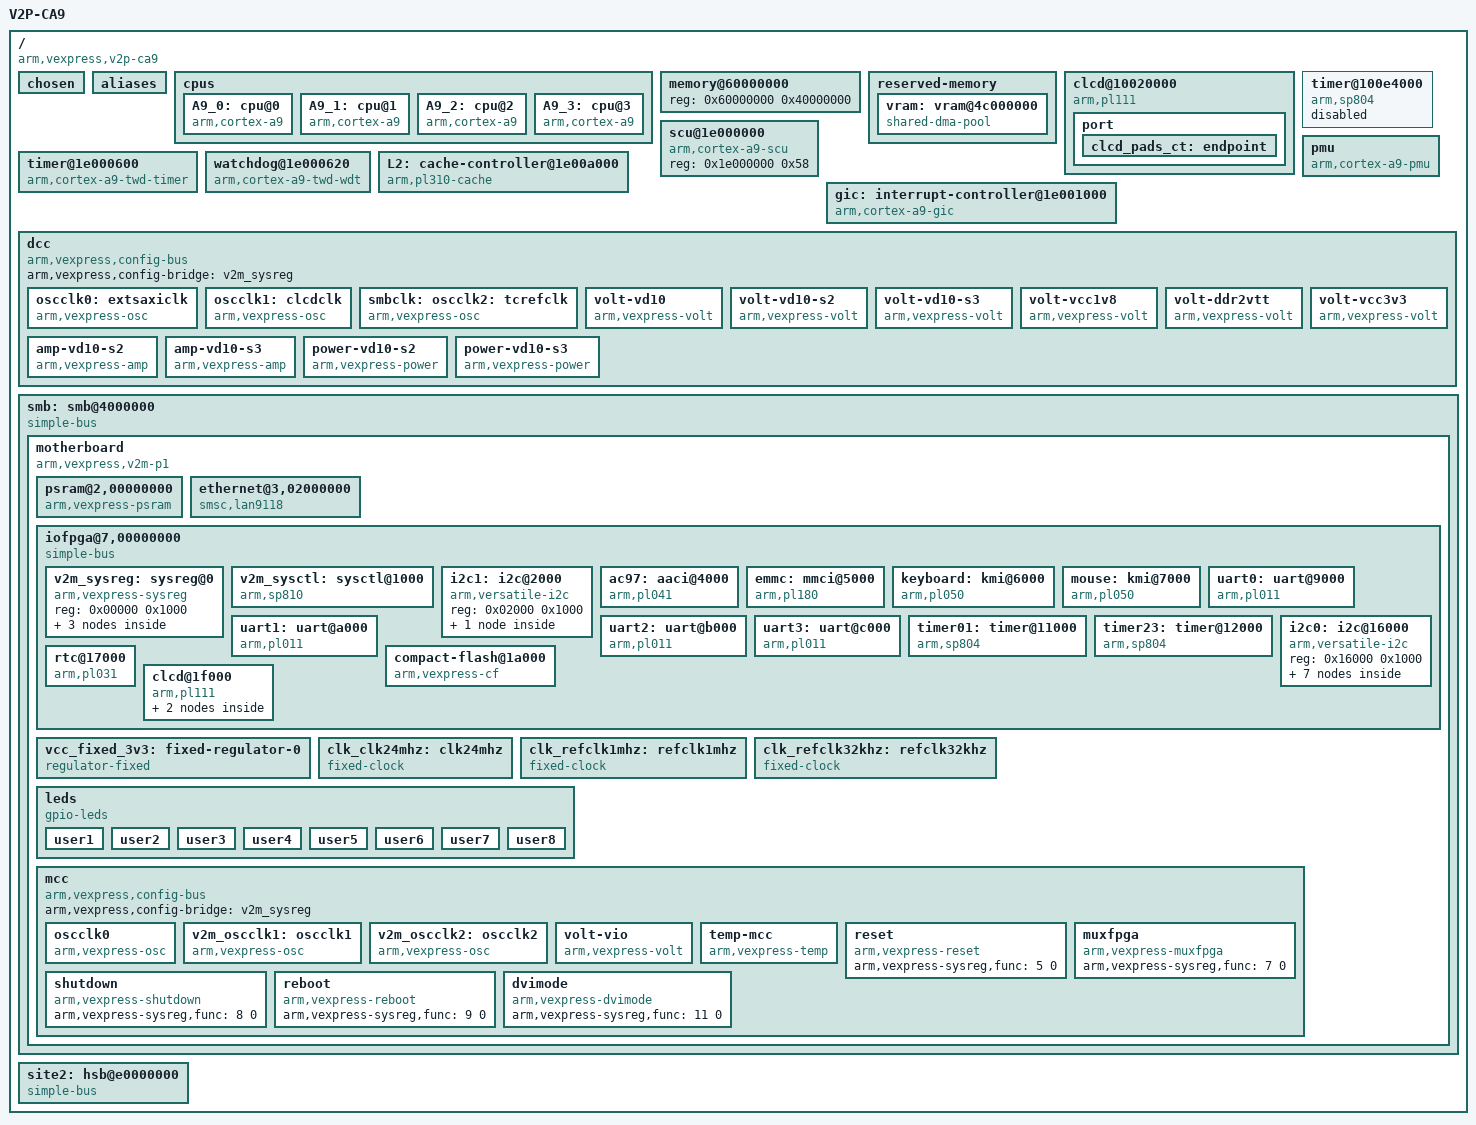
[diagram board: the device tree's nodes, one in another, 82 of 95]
// SPDX-License-Identifier: GPL-2.0
/*
 * ARM Ltd. Versatile Express
 *
 * CoreTile Express A9x4
 * Cortex-A9 MPCore (V2P-CA9)
 *
 * HBI-0191B
 */

/dts-v1/;

/ {
	model = "V2P-CA9";
	arm,hbi = <0x191>;
	arm,vexpress,site = <0xf>;
	compatible = "arm,vexpress,v2p-ca9", "arm,vexpress";
	interrupt-parent = <&gic>;
	#address-cells = <1>;
	#size-cells = <1>;

	chosen { };

	aliases {
		serial0 = &uart0;
		serial1 = &uart1;
		serial2 = &uart2;
		serial3 = &uart3;
		i2c0 = &i2c0;
		i2c1 = &i2c1;
	};

	cpus {
		#address-cells = <1>;
		#size-cells = <0>;

		A9_0: cpu@0 {
			device_type = "cpu";
			compatible = "arm,cortex-a9";
			reg = <0>;
			next-level-cache = <&L2>;
		};

		A9_1: cpu@1 {
			device_type = "cpu";
			compatible = "arm,cortex-a9";
			reg = <1>;
			next-level-cache = <&L2>;
		};

		A9_2: cpu@2 {
			device_type = "cpu";
			compatible = "arm,cortex-a9";
			reg = <2>;
			next-level-cache = <&L2>;
		};

		A9_3: cpu@3 {
			device_type = "cpu";
			compatible = "arm,cortex-a9";
			reg = <3>;
			next-level-cache = <&L2>;
		};
	};

	memory@60000000 {
		device_type = "memory";
		reg = <0x60000000 0x40000000>;
	};

	reserved-memory {
		#address-cells = <1>;
		#size-cells = <1>;
		ranges;

		/* Chipselect 3 is physically at 0x4c000000 */
		vram: vram@4c000000 {
			/* 8 MB of designated video RAM */
			compatible = "shared-dma-pool";
			reg = <0x4c000000 0x00800000>;
			no-map;
		};
	};

	clcd@10020000 {
		compatible = "arm,pl111", "arm,primecell";
		reg = <0x10020000 0x1000>;
		interrupt-names = "combined";
		interrupts = <0 44 4>;
		clocks = <&oscclk1>, <&oscclk2>;
		clock-names = "clcdclk", "apb_pclk";
		/* 1024x768 16bpp @65MHz */
		max-memory-bandwidth = <95000000>;

		port {
			clcd_pads_ct: endpoint {
				remote-endpoint = <&dvi_bridge_in_ct>;
				arm,pl11x,tft-r0g0b0-pads = <0 8 16>;
			};
		};
	};

	timer@100e4000 {
		compatible = "arm,sp804", "arm,primecell";
		reg = <0x100e4000 0x1000>;
		interrupts = <0 48 4>,
			     <0 49 4>;
		clocks = <&oscclk2>, <&oscclk2>;
		clock-names = "timclk", "apb_pclk";
		status = "disabled";
	};

	scu@1e000000 {
		compatible = "arm,cortex-a9-scu";
		reg = <0x1e000000 0x58>;
	};

	timer@1e000600 {
		compatible = "arm,cortex-a9-twd-timer";
		reg = <0x1e000600 0x20>;
		interrupts = <1 13 0xf04>;
	};

	watchdog@1e000620 {
		compatible = "arm,cortex-a9-twd-wdt";
		reg = <0x1e000620 0x20>;
		interrupts = <1 14 0xf04>;
	};

	gic: interrupt-controller@1e001000 {
		compatible = "arm,cortex-a9-gic";
		#interrupt-cells = <3>;
		#address-cells = <0>;
		interrupt-controller;
		reg = <0x1e001000 0x1000>,
		      <0x1e000100 0x100>;
	};

	L2: cache-controller@1e00a000 {
		compatible = "arm,pl310-cache";
		reg = <0x1e00a000 0x1000>;
		interrupts = <0 43 4>;
		cache-unified;
		cache-level = <2>;
		arm,data-latency = <1 1 1>;
		arm,tag-latency = <1 1 1>;
	};

	pmu {
		compatible = "arm,cortex-a9-pmu";
		interrupts = <0 60 4>,
			     <0 61 4>,
			     <0 62 4>,
			     <0 63 4>;
		interrupt-affinity = <&A9_0>, <&A9_1>, <&A9_2>, <&A9_3>;
	};

	dcc {
		compatible = "arm,vexpress,config-bus";
		arm,vexpress,config-bridge = <&v2m_sysreg>;

		oscclk0: extsaxiclk {
			/* ACLK clock to the AXI master port on the test chip */
			compatible = "arm,vexpress-osc";
			arm,vexpress-sysreg,func = <1 0>;
			freq-range = <30000000 50000000>;
			#clock-cells = <0>;
			clock-output-names = "extsaxiclk";
		};

		oscclk1: clcdclk {
			/* Reference clock for the CLCD */
			compatible = "arm,vexpress-osc";
			arm,vexpress-sysreg,func = <1 1>;
			freq-range = <10000000 80000000>;
			#clock-cells = <0>;
			clock-output-names = "clcdclk";
		};

		smbclk: oscclk2: tcrefclk {
			/* Reference clock for the test chip internal PLLs */
			compatible = "arm,vexpress-osc";
			arm,vexpress-sysreg,func = <1 2>;
			freq-range = <33000000 100000000>;
			#clock-cells = <0>;
			clock-output-names = "tcrefclk";
		};

		volt-vd10 {
			/* Test Chip internal logic voltage */
			compatible = "arm,vexpress-volt";
			arm,vexpress-sysreg,func = <2 0>;
			regulator-name = "VD10";
			regulator-always-on;
			label = "VD10";
		};

		volt-vd10-s2 {
			/* PL310, L2 cache, RAM cell supply (not PL310 logic) */
			compatible = "arm,vexpress-volt";
			arm,vexpress-sysreg,func = <2 1>;
			regulator-name = "VD10_S2";
			regulator-always-on;
			label = "VD10_S2";
		};

		volt-vd10-s3 {
			/* Cortex-A9 system supply, Cores, MPEs, SCU and PL310 logic */
			compatible = "arm,vexpress-volt";
			arm,vexpress-sysreg,func = <2 2>;
			regulator-name = "VD10_S3";
			regulator-always-on;
			label = "VD10_S3";
		};

		volt-vcc1v8 {
			/* DDR2 SDRAM and Test Chip DDR2 I/O supply */
			compatible = "arm,vexpress-volt";
			arm,vexpress-sysreg,func = <2 3>;
			regulator-name = "VCC1V8";
			regulator-always-on;
			label = "VCC1V8";
		};

		volt-ddr2vtt {
			/* DDR2 SDRAM VTT termination voltage */
			compatible = "arm,vexpress-volt";
			arm,vexpress-sysreg,func = <2 4>;
			regulator-name = "DDR2VTT";
			regulator-always-on;
			label = "DDR2VTT";
		};

		volt-vcc3v3 {
			/* Local board supply for miscellaneous logic external to the Test Chip */
			arm,vexpress-sysreg,func = <2 5>;
			compatible = "arm,vexpress-volt";
			regulator-name = "VCC3V3";
			regulator-always-on;
			label = "VCC3V3";
		};

		amp-vd10-s2 {
			/* PL310, L2 cache, RAM cell supply (not PL310 logic) */
			compatible = "arm,vexpress-amp";
			arm,vexpress-sysreg,func = <3 0>;
			label = "VD10_S2";
		};

		amp-vd10-s3 {
			/* Cortex-A9 system supply, Cores, MPEs, SCU and PL310 logic */
			compatible = "arm,vexpress-amp";
			arm,vexpress-sysreg,func = <3 1>;
			label = "VD10_S3";
		};

		power-vd10-s2 {
			/* PL310, L2 cache, RAM cell supply (not PL310 logic) */
			compatible = "arm,vexpress-power";
			arm,vexpress-sysreg,func = <12 0>;
			label = "PVD10_S2";
		};

		power-vd10-s3 {
			/* Cortex-A9 system supply, Cores, MPEs, SCU and PL310 logic */
			compatible = "arm,vexpress-power";
			arm,vexpress-sysreg,func = <12 1>;
			label = "PVD10_S3";
		};
	};

	smb: smb@4000000 {
		compatible = "simple-bus";

		#address-cells = <2>;
		#size-cells = <1>;
		ranges = <0 0 0x40000000 0x04000000>,
			 <1 0 0x44000000 0x04000000>,
			 <2 0 0x48000000 0x04000000>,
			 <3 0 0x4c000000 0x04000000>,
			 <7 0 0x10000000 0x00020000>;

		#interrupt-cells = <1>;
		interrupt-map-mask = <0 0 63>;
		interrupt-map = <0 0  0 &gic 0  0 4>,
				<0 0  1 &gic 0  1 4>,
				<0 0  2 &gic 0  2 4>,
				<0 0  3 &gic 0  3 4>,
				<0 0  4 &gic 0  4 4>,
				<0 0  5 &gic 0  5 4>,
				<0 0  6 &gic 0  6 4>,
				<0 0  7 &gic 0  7 4>,
				<0 0  8 &gic 0  8 4>,
				<0 0  9 &gic 0  9 4>,
				<0 0 10 &gic 0 10 4>,
				<0 0 11 &gic 0 11 4>,
				<0 0 12 &gic 0 12 4>,
				<0 0 13 &gic 0 13 4>,
				<0 0 14 &gic 0 14 4>,
				<0 0 15 &gic 0 15 4>,
				<0 0 16 &gic 0 16 4>,
				<0 0 17 &gic 0 17 4>,
				<0 0 18 &gic 0 18 4>,
				<0 0 19 &gic 0 19 4>,
				<0 0 20 &gic 0 20 4>,
				<0 0 21 &gic 0 21 4>,
				<0 0 22 &gic 0 22 4>,
				<0 0 23 &gic 0 23 4>,
				<0 0 24 &gic 0 24 4>,
				<0 0 25 &gic 0 25 4>,
				<0 0 26 &gic 0 26 4>,
				<0 0 27 &gic 0 27 4>,
				<0 0 28 &gic 0 28 4>,
				<0 0 29 &gic 0 29 4>,
				<0 0 30 &gic 0 30 4>,
				<0 0 31 &gic 0 31 4>,
				<0 0 32 &gic 0 32 4>,
				<0 0 33 &gic 0 33 4>,
				<0 0 34 &gic 0 34 4>,
				<0 0 35 &gic 0 35 4>,
				<0 0 36 &gic 0 36 4>,
				<0 0 37 &gic 0 37 4>,
				<0 0 38 &gic 0 38 4>,
				<0 0 39 &gic 0 39 4>,
				<0 0 40 &gic 0 40 4>,
				<0 0 41 &gic 0 41 4>,
				<0 0 42 &gic 0 42 4>;

		motherboard {
			model = "V2M-P1";
			arm,hbi = <0x190>;
			arm,vexpress,site = <0>;
			compatible = "arm,vexpress,v2m-p1", "simple-bus";
			#address-cells = <2>; /* SMB chipselect number and offset */
			#size-cells = <1>;
			#interrupt-cells = <1>;
			ranges;

			psram@2,00000000 {
				compatible = "arm,vexpress-psram", "mtd-ram";
				reg = <2 0x00000000 0x02000000>;
				bank-width = <4>;
			};

			ethernet@3,02000000 {
				compatible = "smsc,lan9118", "smsc,lan9115";
				reg = <3 0x02000000 0x10000>;
				interrupts = <15>;
				phy-mode = "mii";
				reg-io-width = <4>;
				smsc,irq-active-high;
				smsc,irq-push-pull;
				vdd33a-supply = <&vcc_fixed_3v3>;
				vddvario-supply = <&vcc_fixed_3v3>;
			};

			iofpga@7,00000000 {
				compatible = "simple-bus";
				#address-cells = <1>;
				#size-cells = <1>;
				ranges = <0 7 0 0x20000>;

				v2m_sysreg: sysreg@0 {
					compatible = "arm,vexpress-sysreg";
					reg = <0x00000 0x1000>;
					#address-cells = <1>;
					#size-cells = <1>;
					ranges = <0 0 0x1000>;

					v2m_led_gpios: gpio@8 {
						compatible = "arm,vexpress-sysreg,sys_led";
						reg = <0x008 4>;
						gpio-controller;
						#gpio-cells = <2>;
					};

					v2m_mmc_gpios: gpio@48 {
						compatible = "arm,vexpress-sysreg,sys_mci";
						reg = <0x048 4>;
						gpio-controller;
						#gpio-cells = <2>;
					};

					v2m_flash_gpios: gpio@4c {
						compatible = "arm,vexpress-sysreg,sys_flash";
						reg = <0x04c 4>;
						gpio-controller;
						#gpio-cells = <2>;
					};
				};

				v2m_sysctl: sysctl@1000 {
					compatible = "arm,sp810", "arm,primecell";
					reg = <0x01000 0x1000>;
					clocks = <&clk_refclk32khz>, <&clk_refclk1mhz>, <&smbclk>;
					clock-names = "refclk", "timclk", "apb_pclk";
					#clock-cells = <1>;
					clock-output-names = "timerclken0", "timerclken1", "timerclken2", "timerclken3";
					assigned-clocks = <&v2m_sysctl 0>, <&v2m_sysctl 1>, <&v2m_sysctl 3>, <&v2m_sysctl 3>;
					assigned-clock-parents = <&clk_refclk1mhz>, <&clk_refclk1mhz>, <&clk_refclk1mhz>, <&clk_refclk1mhz>;
				};

				/* PCI-E I2C bus */
				i2c1: i2c@2000 {
					compatible = "arm,versatile-i2c";
					reg = <0x02000 0x1000>;

					#address-cells = <1>;
					#size-cells = <0>;

					pcie-switch@60 {
						compatible = "idt,89hpes32h8";
						reg = <0x60>;
					};
				};

				ac97: aaci@4000 {
					compatible = "arm,pl041", "arm,primecell";
					reg = <0x04000 0x1000>;
					interrupts = <11>;
					clocks = <&smbclk>;
					clock-names = "apb_pclk";
				};

				emmc: mmci@5000 {
					compatible = "arm,pl180", "arm,primecell";
					reg = <0x05000 0x1000>;
					interrupts = <9>, <10>;
					cd-gpios = <&v2m_mmc_gpios 0 0>;
					wp-gpios = <&v2m_mmc_gpios 1 0>;
					max-frequency = <12000000>;
					vmmc-supply = <&vcc_fixed_3v3>;
					clocks = <&clk_clk24mhz>, <&smbclk>;
					clock-names = "mclk", "apb_pclk";
				};

				keyboard: kmi@6000 {
					compatible = "arm,pl050", "arm,primecell";
					reg = <0x06000 0x1000>;
					interrupts = <12>;
					clocks = <&clk_clk24mhz>, <&smbclk>;
					clock-names = "KMIREFCLK", "apb_pclk";
				};

				mouse: kmi@7000 {
					compatible = "arm,pl050", "arm,primecell";
					reg = <0x07000 0x1000>;
					interrupts = <13>;
					clocks = <&clk_clk24mhz>, <&smbclk>;
					clock-names = "KMIREFCLK", "apb_pclk";
				};

				uart0: uart@9000 {
					compatible = "arm,pl011", "arm,primecell";
					reg = <0x09000 0x1000>;
					interrupts = <5>;
					clocks = <&v2m_oscclk2>, <&smbclk>;
					clock-names = "uartclk", "apb_pclk";
				};

				uart1: uart@a000 {
					compatible = "arm,pl011", "arm,primecell";
					reg = <0x0a000 0x1000>;
					interrupts = <6>;
					clocks = <&v2m_oscclk2>, <&smbclk>;
					clock-names = "uartclk", "apb_pclk";
				};

				uart2: uart@b000 {
					compatible = "arm,pl011", "arm,primecell";
					reg = <0x0b000 0x1000>;
					interrupts = <7>;
					clocks = <&v2m_oscclk2>, <&smbclk>;
					clock-names = "uartclk", "apb_pclk";
				};

				uart3: uart@c000 {
					compatible = "arm,pl011", "arm,primecell";
					reg = <0x0c000 0x1000>;
					interrupts = <8>;
					clocks = <&v2m_oscclk2>, <&smbclk>;
					clock-names = "uartclk", "apb_pclk";
				};

				timer01: timer@11000 {
					compatible = "arm,sp804", "arm,primecell";
					reg = <0x11000 0x1000>;
					interrupts = <2>;
					clocks = <&v2m_sysctl 0>, <&v2m_sysctl 1>, <&smbclk>;
					clock-names = "timclken1", "timclken2", "apb_pclk";
				};

				timer23: timer@12000 {
					compatible = "arm,sp804", "arm,primecell";
					reg = <0x12000 0x1000>;
					interrupts = <3>;
					clocks = <&v2m_sysctl 2>, <&v2m_sysctl 3>, <&smbclk>;
					clock-names = "timclken1", "timclken2", "apb_pclk";
				};

				i2c0: i2c@16000 {
					compatible = "arm,versatile-i2c";
					reg = <0x16000 0x1000>;
					#address-cells = <1>;
					#size-cells = <0>;

					dvi-transmitter@39 {
						compatible = "sil,sii9022-tpi", "sil,sii9022";
						reg = <0x39>;

						ports {
							#address-cells = <1>;
							#size-cells = <0>;

							/*
							 * Both the core tile and the motherboard routes their output
							 * pads to this transmitter. The motherboard system controller
							 * can select one of them as input using a mux register in
							 * "arm,vexpress-muxfpga". The Vexpress with the CA9 core tile is
							 * the only platform with this specific set-up.
							 */
							port@0 {
								reg = <0>;
								dvi_bridge_in_ct: endpoint {
									remote-endpoint = <&clcd_pads_ct>;
								};
							};
							port@1 {
								reg = <1>;
								dvi_bridge_in_mb: endpoint {
									remote-endpoint = <&clcd_pads_mb>;
								};
							};
						};
					};

					dvi-transmitter@60 {
						compatible = "sil,sii9022-cpi", "sil,sii9022";
						reg = <0x60>;
					};
				};

				rtc@17000 {
					compatible = "arm,pl031", "arm,primecell";
					reg = <0x17000 0x1000>;
					interrupts = <4>;
					clocks = <&smbclk>;
					clock-names = "apb_pclk";
				};

				compact-flash@1a000 {
					compatible = "arm,vexpress-cf", "ata-generic";
					reg = <0x1a000 0x100
					       0x1a100 0xf00>;
					reg-shift = <2>;
				};


				clcd@1f000 {
					compatible = "arm,pl111", "arm,primecell";
					reg = <0x1f000 0x1000>;
					interrupt-names = "combined";
					interrupts = <14>;
					clocks = <&v2m_oscclk1>, <&smbclk>;
					clock-names = "clcdclk", "apb_pclk";
					/* 800x600 16bpp @36MHz works fine */
					max-memory-bandwidth = <54000000>;
					memory-region = <&vram>;

					port {
						clcd_pads_mb: endpoint {
							remote-endpoint = <&dvi_bridge_in_mb>;
							arm,pl11x,tft-r0g0b0-pads = <0 8 16>;
						};
					};
				};
			};

			vcc_fixed_3v3: fixed-regulator-0 {
				compatible = "regulator-fixed";
				regulator-name = "3V3";
				regulator-min-microvolt = <3300000>;
				regulator-max-microvolt = <3300000>;
				regulator-always-on;
			};

			clk_clk24mhz: clk24mhz {
				compatible = "fixed-clock";
				#clock-cells = <0>;
				clock-frequency = <24000000>;
				clock-output-names = "v2m:clk24mhz";
			};

			clk_refclk1mhz: refclk1mhz {
				compatible = "fixed-clock";
				#clock-cells = <0>;
				clock-frequency = <1000000>;
				clock-output-names = "v2m:refclk1mhz";
			};

			clk_refclk32khz: refclk32khz {
				compatible = "fixed-clock";
				#clock-cells = <0>;
				clock-frequency = <32768>;
				clock-output-names = "v2m:refclk32khz";
			};

			leds {
				compatible = "gpio-leds";

				user1 {
					label = "v2m:green:user1";
					gpios = <&v2m_led_gpios 0 0>;
					linux,default-trigger = "heartbeat";
				};

				user2 {
					label = "v2m:green:user2";
					gpios = <&v2m_led_gpios 1 0>;
					linux,default-trigger = "mmc0";
				};

				user3 {
					label = "v2m:green:user3";
					gpios = <&v2m_led_gpios 2 0>;
					linux,default-trigger = "cpu0";
				};

				user4 {
					label = "v2m:green:user4";
					gpios = <&v2m_led_gpios 3 0>;
					linux,default-trigger = "cpu1";
				};

				user5 {
					label = "v2m:green:user5";
					gpios = <&v2m_led_gpios 4 0>;
					linux,default-trigger = "cpu2";
				};

				user6 {
					label = "v2m:green:user6";
					gpios = <&v2m_led_gpios 5 0>;
					linux,default-trigger = "cpu3";
				};

				user7 {
					label = "v2m:green:user7";
					gpios = <&v2m_led_gpios 6 0>;
					linux,default-trigger = "cpu4";
				};

				user8 {
					label = "v2m:green:user8";
					gpios = <&v2m_led_gpios 7 0>;
					linux,default-trigger = "cpu5";
				};
			};

			mcc {
				compatible = "arm,vexpress,config-bus";
				arm,vexpress,config-bridge = <&v2m_sysreg>;

				oscclk0 {
					/* MCC static memory clock */
					compatible = "arm,vexpress-osc";
					arm,vexpress-sysreg,func = <1 0>;
					freq-range = <25000000 60000000>;
					#clock-cells = <0>;
					clock-output-names = "v2m:oscclk0";
				};

				v2m_oscclk1: oscclk1 {
					/* CLCD clock */
					compatible = "arm,vexpress-osc";
					arm,vexpress-sysreg,func = <1 1>;
					freq-range = <23750000 65000000>;
					#clock-cells = <0>;
					clock-output-names = "v2m:oscclk1";
				};

				v2m_oscclk2: oscclk2 {
					/* IO FPGA peripheral clock */
					compatible = "arm,vexpress-osc";
					arm,vexpress-sysreg,func = <1 2>;
					freq-range = <24000000 24000000>;
					#clock-cells = <0>;
					clock-output-names = "v2m:oscclk2";
				};

				volt-vio {
					/* Logic level voltage */
					compatible = "arm,vexpress-volt";
					arm,vexpress-sysreg,func = <2 0>;
					regulator-name = "VIO";
					regulator-always-on;
					label = "VIO";
				};

				temp-mcc {
					/* MCC internal operating temperature */
					compatible = "arm,vexpress-temp";
					arm,vexpress-sysreg,func = <4 0>;
					label = "MCC";
				};

				reset {
					compatible = "arm,vexpress-reset";
					arm,vexpress-sysreg,func = <5 0>;
				};

				muxfpga {
					compatible = "arm,vexpress-muxfpga";
					arm,vexpress-sysreg,func = <7 0>;
				};

				shutdown {
					compatible = "arm,vexpress-shutdown";
					arm,vexpress-sysreg,func = <8 0>;
				};

				reboot {
					compatible = "arm,vexpress-reboot";
					arm,vexpress-sysreg,func = <9 0>;
				};

				dvimode {
					compatible = "arm,vexpress-dvimode";
					arm,vexpress-sysreg,func = <11 0>;
				};
			};
		};
	};

	site2: hsb@e0000000 {
		compatible = "simple-bus";
		#address-cells = <1>;
		#size-cells = <1>;
		ranges = <0 0xe0000000 0x20000000>;
		#interrupt-cells = <1>;
		interrupt-map-mask = <0 3>;
		interrupt-map = <0 0 &gic 0 36 4>,
				<0 1 &gic 0 37 4>,
				<0 2 &gic 0 38 4>,
				<0 3 &gic 0 39 4>;
	};
};
